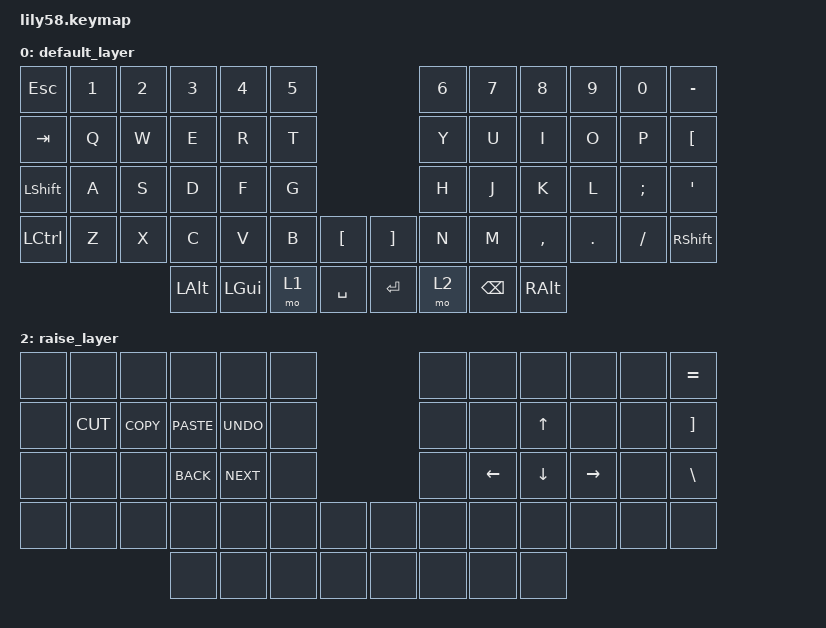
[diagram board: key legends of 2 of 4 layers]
/*
 * Copyright (c) 2020 The ZMK Contributors
 *
 * SPDX-License-Identifier: MIT
 */

#include <behaviors.dtsi>
#include <dt-bindings/zmk/bt.h>
#include <dt-bindings/zmk/ext_power.h>
#include <dt-bindings/zmk/keys.h>
#include <dt-bindings/zmk/mouse.h>

/ {
    keymap {
        compatible = "zmk,keymap";

        default_layer {
            // ------------------------------------------------------------------------------------------------------------
            // |  ESC  |  1  |  2  |  3   |  4   |  5   |                   |  6   |  7    |  8    |  9   |   0   |   +   |
            // |  TAB  |  Q  |  W  |  E   |  R   |  T   |                   |  Y   |  U    |  I    |  O   |   P   |   Å   |
            // | SHIFT |  A  |  S  |  D   |  F   |  G   |                   |  H   |  J    |  K    |  L   |   Ö   |   Ä   |
            // | CTRL  |  Z  |  X  |  C   |  V   |  B   |   "["  |  |  "]"  |  N   |  M    |  ,    |  .   |   -   | SHIFT |
            //                     | ALT  | GUI  | LOWER|  SPACE |  | ENTER | RAISE| BSPC  | RALT  |

            bindings = <
&kp ESC    &kp N1  &kp N2  &kp N3    &kp N4    &kp N5                         &kp N6  &kp N7    &kp N8     &kp N9   &kp N0    &kp MINUS
&kp TAB    &kp Q   &kp W   &kp E     &kp R     &kp T                          &kp Y   &kp U     &kp I      &kp O    &kp P     &kp LBKT
&kp LSHFT  &kp A   &kp S   &kp D     &kp F     &kp G                          &kp H   &kp J     &kp K      &kp L    &kp SEMI  &kp SQT
&kp LCTRL  &kp Z   &kp X   &kp C     &kp V     &kp B   &kp LBKT     &kp RBKT  &kp N   &kp M     &kp COMMA  &kp DOT  &kp FSLH  &kp RSHFT
                           &kp LALT  &kp LGUI  &mo 1   &kp SPACE    &kp RET   &mo 2   &kp BSPC  &kp RALT
            >;
        };

        lower_layer {
            // ------------------------------------------------------------------------------------------------------------
            // |  F1   |  F2 |  F3 |  F4  |  F5  |  F6  |                   |  F7  |  F8   |  F9   |  F10 |  F11  |  F12  |
            // |       |  {  |  }  |  (   |  )   |  [   |                   |      |  INS  | HOME  | PGUP |       |       |
            // |  CAPS |  `  |  '  |  "   |  ;   |  :   |                   |      |  DEL  |  END  | PGDN |       |       |
            // |       |  <  |  >  |  |   |  \   |  &   |        |  |       |      |       |       |      |       |      |
            //                     |      |      |      |        |  |       |      |       |       |

            bindings = <
&kp F1    &kp F2            &kp F3            &kp F4            &kp F5            &kp F6                            &kp F7     &kp F8      &kp F9    &kp F10    &kp F11  &kp F12
&none     &kp RA(N8)        &kp RA(NUMBER_9)  &kp LS(NUMBER_8)  &kp LS(NUMBER_9)  &none                             &none      &kp INSERT  &kp HOME  &kp PG_UP  &none    &none
&kp CAPS  &kp SINGLE_QUOTE  &kp LS(NUMBER_2)  &kp RA(NUMBER_7)  &kp RA(NUMBER_0)  &none                             &none      &kp DEL     &kp END   &kp PG_DN  &none    &none
&none     &kp NUBS          &kp NUHS          &kp PIPE          &kp BSLH          &kp AMPS  &kp LS(A)    &kp LS(D)  &mkp LCLK  &mkp RCLK   &none     &none      &none    &none
                                              &none             &none             &none     &none        &none      &none
            >;
        };

        raise_layer {
            // ------------------------------------------------------------------------------------------------------------
            // |       |     |     |      |      |      |                   |      |       |       |      |       |       |
            // |       | CUT | COPY|PASTE | UNDO |      |                   |      |       |  UP   |      |       |       |
            // |       |     |     |      |      |      |                   |      | LEFT  | DOWN  | RIGHT|       |       |
            // |       |     |     |      |      |      |        |  |       |      |       |       |      |       |       |
            //                     |      |      |      |        |  |       |      |       |       |

            bindings = <
&none  &none      &none       &none        &none       &none                  &none  &none     &none     &none      &none  &kp EQUAL
&none  &kp K_CUT  &kp K_COPY  &kp K_PASTE  &kp K_UNDO  &none                  &none  &none     &kp UP    &none      &none  &kp RIGHT_BRACKET
&none  &none      &none       &kp K_BACK   &kp K_NEXT  &none                  &none  &kp LEFT  &kp DOWN  &kp RIGHT  &none  &kp BACKSLASH
&none  &none      &none       &none        &none       &none  &none    &none  &none  &none     &none     &none      &none  &none
                              &none        &none       &none  &none    &none  &none  &none     &none
            >;
        };

        adjust_layer {
            // ------------------------------------------------------------------------------------------------------------
            // | BTCLR | BT1 | BT2 |  BT3 |  BT4 |  BT5 |                   |      |       |       |BR_UP |BR_DN  |CALC   |
            // |       |     |     |      |      |      |                   |      |       |       |VOL_UP|VOL_DN |MUTE   |
            // |       |     |     |      |      |      |                   |      |       |       |      |       |       |
            // |       |     |     |      |      |      |        |  |       |      |       |       |      |       |      |
            //                     |      |      |      |        |  |       |      |       |       |

            bindings = <
&bt BT_CLR  &bt BT_SEL 0      &bt BT_SEL 1       &bt BT_SEL 2          &bt BT_SEL 3     &bt BT_SEL 4                  &none  &none  &kp KP_NUMBER_7  &kp KP_NUMBER_8  &kp KP_NUMBER_9  &kp KP_MINUS
&none       &none             &none              &kp C_BRIGHTNESS_INC  &kp C_VOLUME_UP  &kp K_CALC                    &none  &none  &kp KP_NUMBER_4  &kp KP_NUMBER_5  &kp KP_NUMBER_6  &kp KP_PLUS
&none       &none             &none              &kp C_BRIGHTNESS_INC  &kp C_VOL_DN     &none                         &none  &none  &kp KP_NUMBER_1  &kp KP_NUMBER_2  &kp KP_NUMBER_3  &kp KP_MULTIPLY
&none       &ext_power EP_ON  &ext_power EP_OFF  &ext_power EP_TOG     &kp C_MUTE       &none         &none    &none  &none  &none  &none            &kp KP_NUMBER_0  &kp LS(KP_DOT)   &kp KP_DIVIDE
                                                 &none                 &none            &none         &none    &none  &none
            >;
        };
    };

    combos {
        compatible = "zmk,combos";

        combo_0 {
            timeout-ms = <50>;
            key-positions = <21 27>; // Key positions for LOWER and RAISE
            bindings = <&mo 3>;  // Activate the adjust layer when both LOWER and RAISE are pressed
        };
    };

    conditional_layers {
        compatible = "zmk,conditional-layers";

        tri_layer {
            if-layers = <1 2>;
            then-layer = <3>;
        };
    };
};
